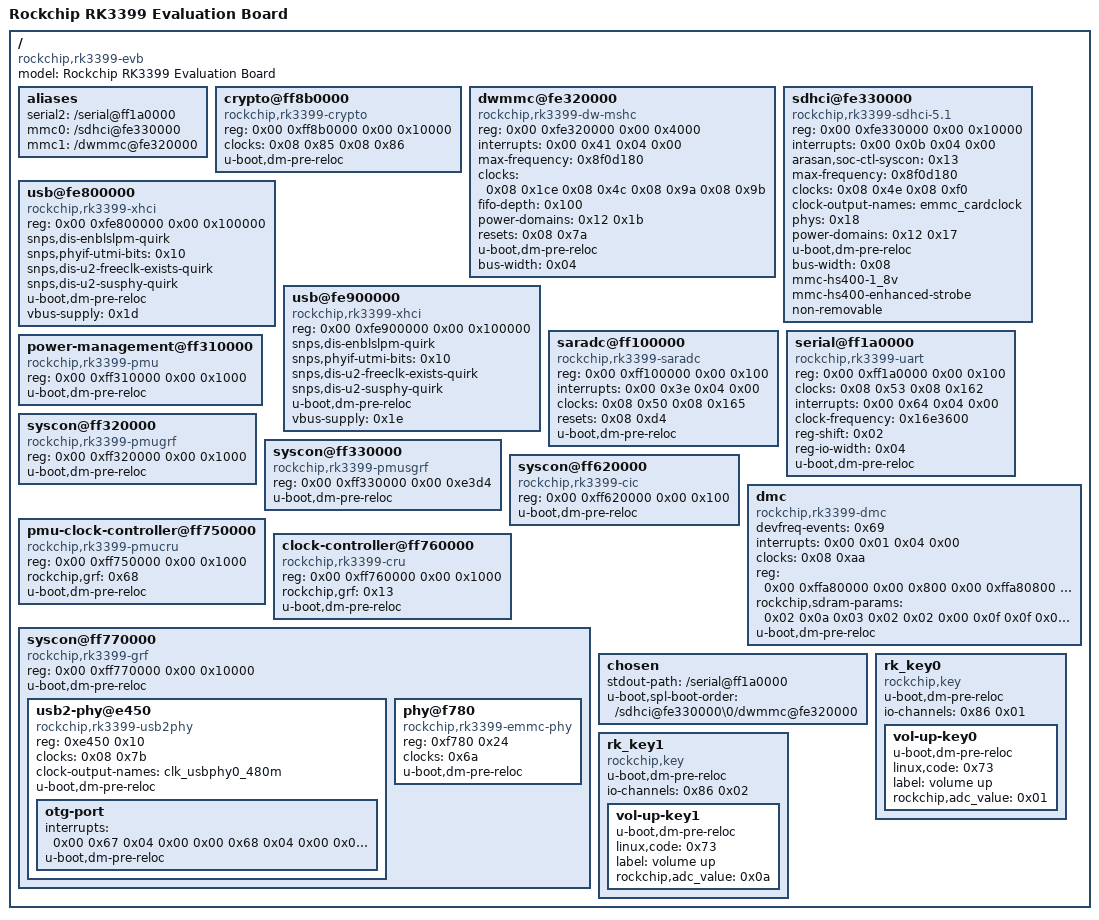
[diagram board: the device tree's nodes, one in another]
/dts-v1/;

/ {
	compatible = "rockchip,rk3399-evb\0rockchip,rk3399\0google,rk3399evb-rev2";
	#address-cells = <0x02>;
	#size-cells = <0x02>;
	model = "Rockchip RK3399 Evaluation Board";

	aliases {
		serial2 = "/serial@ff1a0000";
		mmc0 = "/sdhci@fe330000";
		mmc1 = "/dwmmc@fe320000";
	};

	crypto@ff8b0000 {
		compatible = "rockchip,rk3399-crypto";
		reg = <0x00 0xff8b0000 0x00 0x10000>;
		clocks = <0x08 0x85 0x08 0x86>;
		status = "okay";
		u-boot,dm-pre-reloc;
	};

	dwmmc@fe320000 {
		compatible = "rockchip,rk3399-dw-mshc\0rockchip,rk3288-dw-mshc";
		reg = <0x00 0xfe320000 0x00 0x4000>;
		interrupts = <0x00 0x41 0x04 0x00>;
		max-frequency = <0x8f0d180>;
		clocks = <0x08 0x1ce 0x08 0x4c 0x08 0x9a 0x08 0x9b>;
		fifo-depth = <0x100>;
		power-domains = <0x12 0x1b>;
		resets = <0x08 0x7a>;
		reset-names = "reset";
		status = "okay";
		u-boot,dm-pre-reloc;
		bus-width = <0x04>;
	};

	sdhci@fe330000 {
		compatible = "rockchip,rk3399-sdhci-5.1\0arasan,sdhci-5.1";
		reg = <0x00 0xfe330000 0x00 0x10000>;
		interrupts = <0x00 0x0b 0x04 0x00>;
		arasan,soc-ctl-syscon = <0x13>;
		max-frequency = <0x8f0d180>;
		clocks = <0x08 0x4e 0x08 0xf0>;
		clock-output-names = "emmc_cardclock";
		#clock-cells = <0x00>;
		phys = <0x18>;
		phy-names = "phy_arasan";
		power-domains = <0x12 0x17>;
		status = "okay";
		u-boot,dm-pre-reloc;
		bus-width = <0x08>;
		mmc-hs400-1_8v;
		mmc-hs400-enhanced-strobe;
		non-removable;
		phandle = <0x6a>;
	};

	usb@fe800000 {
		compatible = "rockchip,rk3399-xhci";
		reg = <0x00 0xfe800000 0x00 0x100000>;
		status = "okay";
		snps,dis-enblslpm-quirk;
		snps,phyif-utmi-bits = <0x10>;
		snps,dis-u2-freeclk-exists-quirk;
		snps,dis-u2-susphy-quirk;
		#address-cells = <0x02>;
		#size-cells = <0x02>;
		u-boot,dm-pre-reloc;
		vbus-supply = <0x1d>;
	};

	usb@fe900000 {
		compatible = "rockchip,rk3399-xhci";
		reg = <0x00 0xfe900000 0x00 0x100000>;
		status = "okay";
		snps,dis-enblslpm-quirk;
		snps,phyif-utmi-bits = <0x10>;
		snps,dis-u2-freeclk-exists-quirk;
		snps,dis-u2-susphy-quirk;
		#address-cells = <0x02>;
		#size-cells = <0x02>;
		u-boot,dm-pre-reloc;
		vbus-supply = <0x1e>;
	};

	saradc@ff100000 {
		compatible = "rockchip,rk3399-saradc";
		reg = <0x00 0xff100000 0x00 0x100>;
		interrupts = <0x00 0x3e 0x04 0x00>;
		#io-channel-cells = <0x01>;
		clocks = <0x08 0x50 0x08 0x165>;
		resets = <0x08 0xd4>;
		reset-names = "saradc-apb";
		status = "okay";
		u-boot,dm-pre-reloc;
		phandle = <0x86>;
	};

	serial@ff1a0000 {
		compatible = "rockchip,rk3399-uart\0snps,dw-apb-uart";
		reg = <0x00 0xff1a0000 0x00 0x100>;
		clocks = <0x08 0x53 0x08 0x162>;
		interrupts = <0x00 0x64 0x04 0x00>;
		clock-frequency = <0x16e3600>;
		reg-shift = <0x02>;
		reg-io-width = <0x04>;
		status = "okay";
		u-boot,dm-pre-reloc;
	};

	power-management@ff310000 {
		compatible = "rockchip,rk3399-pmu\0syscon\0simple-mfd";
		reg = <0x00 0xff310000 0x00 0x1000>;
		u-boot,dm-pre-reloc;
	};

	syscon@ff320000 {
		compatible = "rockchip,rk3399-pmugrf\0syscon\0simple-mfd";
		reg = <0x00 0xff320000 0x00 0x1000>;
		#address-cells = <0x01>;
		#size-cells = <0x01>;
		u-boot,dm-pre-reloc;
		phandle = <0x68>;
	};

	syscon@ff330000 {
		compatible = "rockchip,rk3399-pmusgrf\0syscon";
		reg = <0x00 0xff330000 0x00 0xe3d4>;
		u-boot,dm-pre-reloc;
	};

	syscon@ff620000 {
		compatible = "rockchip,rk3399-cic\0syscon";
		reg = <0x00 0xff620000 0x00 0x100>;
		u-boot,dm-pre-reloc;
	};

	dmc {
		compatible = "rockchip,rk3399-dmc";
		devfreq-events = <0x69>;
		interrupts = <0x00 0x01 0x04 0x00>;
		clocks = <0x08 0xaa>;
		reg = <0x00 0xffa80000 0x00 0x800 0x00 0xffa80800 0x00 0x1800 0x00 0xffa82000 0x00 0x2000 0x00 0xffa84000 0x00 0x1000 0x00 0xffa88000 0x00 0x800 0x00 0xffa88800 0x00 0x1800 0x00 0xffa8a000 0x00 0x2000 0x00 0xffa8c000 0x00 0x1000>;
		rockchip,sdram-params = <0x02 0x0a 0x03 0x02 0x02 0x00 0x0f 0x0f 0x0f 0x0f 0x01 0x1d191519 0x14040808 0x02 0x6226 0x54 0x00 0x02 0x0a 0x03 0x02 0x02 0x00 0x0f 0x0f 0x0f 0x0f 0x01 0x1d191519 0x14040808 0x02 0x6226 0x54 0x00 0x320 0x06 0x02 0x0d 0x01 0x700 0x00 0x00 0x00 0x00 0x50 0x27100 0x320 0x1f40 0x50 0x27100 0x320 0x1f40 0x50 0x27100 0x320 0x1001f40 0x00 0x101 0x20100 0xa0 0x190 0x00 0x6180000 0x61800 0x4000618 0x33080004 0x280f0622 0x22330800 0x280f06 0x6223308 0x600280f 0xa0a 0x600dac0 0xa0a060c 0x600dac0 0xa0a060c 0x600dac0 0x203000c 0xf0c0f00 0x40c0f0c 0x14000a0a 0x3030a0a 0x10003 0x31b1b1b 0x111111 0x00 0x3010000 0xc2800a8 0xc2800a8 0xc2800a8 0x00 0x60006 0x140006 0x140014 0xf0f0f 0x00 0x00 0x00 0xb00000 0xb000b0 0xb000b0 0xb0 0x00 0x00 0x00 0x00 0x00 0x00 0x301 0x01 0x00 0x00 0x1000000 0x80104002 0x40003 0x40005 0x30000 0x50004 0x04 0x40003 0x40005 0x30a00000 0x1850 0x185030a0 0x30a00000 0x1850 0x00 0x00 0x00 0x00 0x00 0x2020200 0x20202 0x30200 0x40700 0x302 0x2000407 0x03 0x30f04 0x70004 0x00 0x00 0x00 0x00 0x00 0x00 0x00 0x10000 0x20040020 0x200400 0x1000400 0xb80 0x00 0x01 0x02 0x0e 0x00 0x00 0x00 0x00 0x00 0xa00000 0xc80050 0xc80000 0x5000a0 0xc8 0xa000c8 0xc80050 0xc80000 0x00 0x00 0x00 0x430000 0x1a 0x1a0043 0x430000 0x1a 0x10001 0x7000001 0x707 0x00 0x00 0x00 0x00 0x00 0x00 0x430000 0x1a 0x1a0043 0x430000 0x1a 0x10001 0x7000001 0x707 0x00 0x00 0x00 0x00 0x00 0x00 0x1000000 0x00 0x00 0x18151100 0x0c 0x00 0x00 0x00 0x00 0x00 0x00 0x00 0x00 0x00 0x00 0x00 0x00 0x00 0x32003 0x480120 0x00 0x1200320 0x48 0x32000 0x480120 0x00 0x280000 0x280028 0x1010100 0x1000202 0xa000002 0x1000f0f 0x00 0x00 0x10003 0xc03 0x100 0x10000 0x1000000 0x10000 0x01 0x00 0x00 0x00 0x00 0x00 0x00 0x00 0x00 0x00 0x10000 0x3030301 0x1010808 0x3030001 0xa0a0a03 0x2080808 0x2050103 0x2050103 0x50103 0x20202 0x5020500 0x20502 0x00 0x00 0xd000001 0x10028 0x10000 0x03 0x00 0x00 0x00 0x00 0x00 0x00 0x00 0x00 0x10100 0x1000000 0x01 0x303 0x00 0x00 0x00 0x00 0x00 0x00 0x00 0x00 0x00 0x00 0x00 0x00 0x00 0x00 0x00 0x556aa 0xaaaaa 0xaa955 0x55555 0xb3133 0x4cd33 0x4cecc 0xb32cc 0x10300 0x3000100 0x00 0x00 0x00 0x00 0x00 0x00 0x00 0x00 0xffff00 0x1e1e0000 0x800001e 0x1850 0x200 0x200 0x200 0x200 0x1850 0xf320 0x1850050a 0x200 0x200 0x200 0x200 0x1850 0xf320 0x1850050a 0x200 0x200 0x200 0x200 0x1850 0xf320 0x202050a 0x3030202 0x18 0x00 0x00 0x1403 0x00 0x00 0x00 0x30000 0xe0020 0xe0020 0xe0020 0x00 0x00 0x1000000 0x70007 0x50007 0x00 0x00 0x00 0x00 0x00 0x00 0x00 0x00 0x1000101 0x1010101 0x1000101 0x1000100 0x10001 0x10002 0x20100 0x02 0x700 0x00 0x30a0 0x1850 0x30a0 0x1850 0x30a0 0x18501850 0x200 0x200 0x200 0x200 0x1850 0x200 0x200 0x200 0x200 0x1850 0x200 0x200 0x200 0x200 0x10000 0x07 0x81000001 0xf0003f0 0x3fffffff 0xf0000a0 0x377ff000 0xf000020 0x377ff000 0xf000030 0x377ff000 0xf0000b0 0x377ff000 0xf000100 0x377ff000 0xf000110 0x377ff000 0xf000010 0x377ff000 0x3000101 0x42e2e2e 0x6180006 0x61800 0x18 0xc2800a8 0xc2800a8 0xc2800a8 0x500 0x00 0x00 0x00 0x00 0x00 0x00 0x00 0x00 0x4040000 0xd000004 0x128 0x00 0x30003 0x18 0x00 0x00 0x3060002 0x3010301 0x1080801 0x4020201 0x1080804 0x00 0x3030000 0xa0a0a03 0x00 0x00 0x00 0x30300 0x14 0x00 0x1010300 0x00 0x00 0x1000000 0x101 0x55555a5a 0x55555a5a 0x55555a5a 0x55555a5a 0xa0a0001 0x505000a 0x05 0x100 0x30000 0x17030000 0xe0020 0xe0020 0xe0020 0x00 0x00 0x100 0x140a0000 0xa030a 0x3000a03 0x10a000a 0x100 0x1000000 0x00 0x100 0x1e1a0000 0x10010204 0x7070705 0x20000202 0x201000 0x201000 0x4041000 0x10100100 0x10110 0x4b004a 0x1a030000 0x102041e 0x34000000 0x00 0x00 0x00 0x4300 0x1001a 0x4d4d07 0x1a0043 0x4d070001 0x434d 0x1001a 0x4d4d07 0x1a0043 0x4d070001 0x434d 0x1001a 0x4d4d07 0x1a0043 0x4d070001 0x43004d 0x1001a 0x4d4d07 0x1a0043 0x4d070001 0x434d 0x1001a 0x4d4d07 0x1a0043 0x4d070001 0x434d 0x1001a 0x4d4d07 0x1a0043 0x4d070001 0x100004d 0xc800c8 0x60400c8 0xc060f11 0x2200d890 0xa0c2005 0xf11060a 0xc06 0x2200d890 0xa0c2005 0xf11060a 0xc06 0x2200d890 0xa0c2005 0x200020a 0x2000200 0x2000200 0x2000200 0x2000200 0x00 0x00 0x00 0x00 0x00 0x00 0x00 0x00 0x00 0x00 0x00 0x00 0x1000300 0x185000 0xf320 0x1850 0xf320 0x1850 0xf320 0x8000000 0x100 0x00 0x00 0x00 0x00 0x02 0x76543210 0x4c008 0xb3 0x00 0x00 0x10000 0x1665555 0x665555 0x10f00 0x5010200 0x03 0x1700c0 0xcc0101 0x30066 0x00 0x00 0x00 0x00 0x00 0x00 0x00 0x00 0x4080000 0x4080400 0x8000000 0xc00c007 0x100 0x100 0x55555555 0xaaaaaaaa 0x55555555 0xaaaaaaaa 0x5555 0x00 0x00 0x00 0x00 0x00 0x00 0x00 0x00 0x00 0x00 0x00 0x00 0x00 0x00 0x00 0x00 0x00 0x00 0x00 0x200000 0x00 0x00 0x00 0x00 0x00 0x00 0x2700270 0x2700270 0x2700270 0x2700270 0x270 0x00 0x00 0x00 0x00 0x800000 0x800080 0x800080 0x800080 0x800080 0x800080 0x800080 0x800080 0x800080 0xb30080 0x03 0x00 0x20000 0x200 0x00 0x51315152 0xc0013150 0x20000c0 0x100001 0x7054208 0xf0c18 0x1000140 0xc20 0x00 0x00 0x00 0x00 0x00 0x00 0x00 0x00 0x00 0x00 0x00 0x00 0x00 0x00 0x00 0x00 0x00 0x00 0x00 0x00 0x00 0x00 0x00 0x00 0x00 0x00 0x00 0x00 0x00 0x00 0x00 0x00 0x00 0x00 0x00 0x00 0x00 0x76543210 0x4c008 0xb3 0x00 0x00 0x10000 0x1665555 0x665555 0x10f00 0x5010200 0x03 0x1700c0 0xcc0101 0x30066 0x00 0x00 0x00 0x00 0x00 0x00 0x00 0x00 0x4080000 0x4080400 0x8000000 0xc00c007 0x100 0x100 0x55555555 0xaaaaaaaa 0x55555555 0xaaaaaaaa 0x5555 0x00 0x00 0x00 0x00 0x00 0x00 0x00 0x00 0x00 0x00 0x00 0x00 0x00 0x00 0x00 0x00 0x00 0x00 0x00 0x200000 0x00 0x00 0x00 0x00 0x00 0x00 0x2700270 0x2700270 0x2700270 0x2700270 0x270 0x00 0x00 0x00 0x00 0x800000 0x800080 0x800080 0x800080 0x800080 0x800080 0x800080 0x800080 0x800080 0xb30080 0x03 0x00 0x20000 0x200 0x00 0x51315152 0xc0013150 0x20000c0 0x100001 0x7054208 0xf0c18 0x1000140 0xc20 0x00 0x00 0x00 0x00 0x00 0x00 0x00 0x00 0x00 0x00 0x00 0x00 0x00 0x00 0x00 0x00 0x00 0x00 0x00 0x00 0x00 0x00 0x00 0x00 0x00 0x00 0x00 0x00 0x00 0x00 0x00 0x00 0x00 0x00 0x00 0x00 0x00 0x76543210 0x4c008 0xb3 0x00 0x00 0x10000 0x1665555 0x665555 0x10f00 0x5010200 0x03 0x1700c0 0xcc0101 0x30066 0x00 0x00 0x00 0x00 0x00 0x00 0x00 0x00 0x4080000 0x4080400 0x8000000 0xc00c007 0x100 0x100 0x55555555 0xaaaaaaaa 0x55555555 0xaaaaaaaa 0x5555 0x00 0x00 0x00 0x00 0x00 0x00 0x00 0x00 0x00 0x00 0x00 0x00 0x00 0x00 0x00 0x00 0x00 0x00 0x00 0x200000 0x00 0x00 0x00 0x00 0x00 0x00 0x2700270 0x2700270 0x2700270 0x2700270 0x270 0x00 0x00 0x00 0x00 0x800000 0x800080 0x800080 0x800080 0x800080 0x800080 0x800080 0x800080 0x800080 0xb30080 0x03 0x00 0x20000 0x200 0x00 0x51315152 0xc0013150 0x20000c0 0x100001 0x7054208 0xf0c18 0x1000140 0xc20 0x00 0x00 0x00 0x00 0x00 0x00 0x00 0x00 0x00 0x00 0x00 0x00 0x00 0x00 0x00 0x00 0x00 0x00 0x00 0x00 0x00 0x00 0x00 0x00 0x00 0x00 0x00 0x00 0x00 0x00 0x00 0x00 0x00 0x00 0x00 0x00 0x00 0x76543210 0x4c008 0xb3 0x00 0x00 0x10000 0x1665555 0x665555 0x10f00 0x5010200 0x03 0x1700c0 0xcc0101 0x30066 0x00 0x00 0x00 0x00 0x00 0x00 0x00 0x00 0x4080000 0x4080400 0x8000000 0xc00c007 0x100 0x100 0x55555555 0xaaaaaaaa 0x55555555 0xaaaaaaaa 0x5555 0x00 0x00 0x00 0x00 0x00 0x00 0x00 0x00 0x00 0x00 0x00 0x00 0x00 0x00 0x00 0x00 0x00 0x00 0x00 0x200000 0x00 0x00 0x00 0x00 0x00 0x00 0x2700270 0x2700270 0x2700270 0x2700270 0x270 0x00 0x00 0x00 0x00 0x800000 0x800080 0x800080 0x800080 0x800080 0x800080 0x800080 0x800080 0x800080 0xb30080 0x03 0x00 0x20000 0x200 0x00 0x51315152 0xc0013150 0x20000c0 0x100001 0x7054208 0xf0c18 0x1000140 0xc20 0x00 0x00 0x00 0x00 0x00 0x00 0x00 0x00 0x00 0x00 0x00 0x00 0x00 0x00 0x00 0x00 0x00 0x00 0x00 0x00 0x00 0x00 0x00 0x00 0x00 0x00 0x00 0x00 0x00 0x00 0x00 0x00 0x00 0x00 0x00 0x00 0x00 0x00 0x800000 0x00 0x00 0x00 0x00 0x00 0x01 0x00 0x00 0x00 0x400320 0x40 0x806420 0x917531 0x806420 0x1917531 0x20003 0x00 0x00 0x00 0x556aa 0xaaaaa 0xaa955 0x55555 0xb3133 0x4cd33 0x4cecc 0xb32cc 0xa418820 0x103f0000 0x3f 0x38055 0x3800380 0x3800380 0x380 0x42080010 0x03 0x00 0x00 0x00 0x00 0x00 0x00 0x00 0x00 0x00 0x00 0x00 0x00 0x00 0x00 0x00 0x00 0x00 0x00 0x00 0x00 0x00 0x00 0x00 0x00 0x00 0x00 0x00 0x00 0x00 0x00 0x00 0x00 0x00 0x00 0x00 0x00 0x00 0x00 0x00 0x00 0x00 0x00 0x00 0x00 0x00 0x00 0x00 0x00 0x00 0x00 0x00 0x00 0x00 0x00 0x00 0x00 0x00 0x00 0x00 0x00 0x00 0x00 0x00 0x00 0x00 0x00 0x00 0x00 0x00 0x00 0x00 0x00 0x00 0x00 0x00 0x00 0x00 0x00 0x00 0x00 0x00 0x00 0x00 0x00 0x00 0x00 0x00 0x00 0x00 0x00 0x00 0x800000 0x00 0x00 0x00 0x00 0x00 0x01 0x00 0x00 0x00 0x400320 0x40 0x8eca 0x9fdb 0x8eca 0x1009fdb 0x20003 0x00 0x00 0x00 0x556aa 0xaaaaa 0xaa955 0x55555 0xb3133 0x4cd33 0x4cecc 0xb32cc 0x4a0e6 0x80f0000 0x0f 0x38055 0x3800380 0x3800380 0x380 0x42080010 0x03 0x00 0x00 0x00 0x00 0x00 0x00 0x00 0x00 0x00 0x00 0x00 0x00 0x00 0x00 0x00 0x00 0x00 0x00 0x00 0x00 0x00 0x00 0x00 0x00 0x00 0x00 0x00 0x00 0x00 0x00 0x00 0x00 0x00 0x00 0x00 0x00 0x00 0x00 0x00 0x00 0x00 0x00 0x00 0x00 0x00 0x00 0x00 0x00 0x00 0x00 0x00 0x00 0x00 0x00 0x00 0x00 0x00 0x00 0x00 0x00 0x00 0x00 0x00 0x00 0x00 0x00 0x00 0x00 0x00 0x00 0x00 0x00 0x00 0x00 0x00 0x00 0x00 0x00 0x00 0x00 0x00 0x00 0x00 0x00 0x00 0x00 0x00 0x00 0x00 0x00 0x00 0x800000 0x00 0x00 0x00 0x00 0x00 0x01 0x00 0x00 0x00 0x400320 0x40 0x8eca 0x9fdb 0x8eca 0x1009fdb 0x20003 0x00 0x00 0x00 0x556aa 0xaaaaa 0xaa955 0x55555 0xb3133 0x4cd33 0x4cecc 0xb32cc 0x1ee6b16a 0x10000000 0x00 0x38055 0x3800380 0x3800380 0x380 0x42080010 0x03 0x00 0x00 0x00 0x00 0x00 0x00 0x00 0x00 0x00 0x00 0x00 0x00 0x00 0x00 0x00 0x00 0x00 0x00 0x00 0x00 0x00 0x00 0x00 0x00 0x00 0x00 0x00 0x00 0x00 0x00 0x00 0x00 0x00 0x00 0x00 0x00 0x00 0x00 0x00 0x00 0x00 0x00 0x00 0x00 0x00 0x00 0x00 0x00 0x00 0x00 0x00 0x00 0x00 0x00 0x00 0x00 0x00 0x00 0x00 0x00 0x00 0x00 0x00 0x00 0x00 0x00 0x00 0x00 0x00 0x00 0x00 0x00 0x00 0x00 0x00 0x00 0x00 0x00 0x00 0x00 0x00 0x00 0x00 0x00 0x00 0x00 0x00 0x00 0x00 0x00 0x01 0x00 0x1000005 0x4000f00 0x20040 0x20055 0x00 0x00 0x00 0x50 0x00 0x10100 0x601 0x00 0x6400 0x1221102 0x00 0x51f00 0x51f051f 0x51f051f 0x30003 0x3000300 0x300 0x1221102 0x00 0x00 0x3020000 0x01 0x11 0x11 0x400 0x00 0x11 0x11 0x4410 0x4410 0x4410 0x4410 0x4410 0x11 0x4410 0x11 0x4410 0x11 0x4410 0x00 0x00 0x00 0x4000000 0x00 0x00 0x508 0x00 0x00 0x00 0x00 0x00 0x00 0xe4000000 0x00 0x00 0x1010000 0x00>;
		u-boot,dm-pre-reloc;
	};

	pmu-clock-controller@ff750000 {
		compatible = "rockchip,rk3399-pmucru";
		reg = <0x00 0xff750000 0x00 0x1000>;
		rockchip,grf = <0x68>;
		#clock-cells = <0x01>;
		#reset-cells = <0x01>;
		u-boot,dm-pre-reloc;
		phandle = <0x5c>;
	};

	clock-controller@ff760000 {
		compatible = "rockchip,rk3399-cru";
		reg = <0x00 0xff760000 0x00 0x1000>;
		rockchip,grf = <0x13>;
		#clock-cells = <0x01>;
		#reset-cells = <0x01>;
		u-boot,dm-pre-reloc;
		phandle = <0x08>;
	};

	syscon@ff770000 {
		compatible = "rockchip,rk3399-grf\0syscon\0simple-mfd";
		reg = <0x00 0xff770000 0x00 0x10000>;
		#address-cells = <0x01>;
		#size-cells = <0x01>;
		u-boot,dm-pre-reloc;
		phandle = <0x13>;

		usb2-phy@e450 {
			compatible = "rockchip,rk3399-usb2phy";
			reg = <0xe450 0x10>;
			clocks = <0x08 0x7b>;
			#clock-cells = <0x00>;
			clock-output-names = "clk_usbphy0_480m";
			status = "okay";
			u-boot,dm-pre-reloc;
			phandle = <0x19>;

			otg-port {
				#phy-cells = <0x00>;
				interrupts = <0x00 0x67 0x04 0x00 0x00 0x68 0x04 0x00 0x00 0x6a 0x04 0x00>;
				interrupt-names = "otg-bvalid\0otg-id\0linestate";
				status = "okay";
				u-boot,dm-pre-reloc;
			};
		};

		phy@f780 {
			compatible = "rockchip,rk3399-emmc-phy";
			reg = <0xf780 0x24>;
			clocks = <0x6a>;
			#phy-cells = <0x00>;
			status = "okay";
			u-boot,dm-pre-reloc;
			phandle = <0x18>;
		};
	};

	chosen {
		stdout-path = "/serial@ff1a0000";
		u-boot,spl-boot-order = "/sdhci@fe330000\0/dwmmc@fe320000";
	};

	rk_key0 {
		u-boot,dm-pre-reloc;
		compatible = "rockchip,key";
		status = "okay";
		io-channels = <0x86 0x01>;

		vol-up-key0 {
			u-boot,dm-pre-reloc;
			linux,code = <0x73>;
			label = "volume up";
			rockchip,adc_value = <0x01>;
		};
	};

	rk_key1 {
		u-boot,dm-pre-reloc;
		compatible = "rockchip,key";
		status = "okay";
		io-channels = <0x86 0x02>;

		vol-up-key1 {
			u-boot,dm-pre-reloc;
			linux,code = <0x73>;
			label = "volume up";
			rockchip,adc_value = <0x0a>;
		};
	};
};
